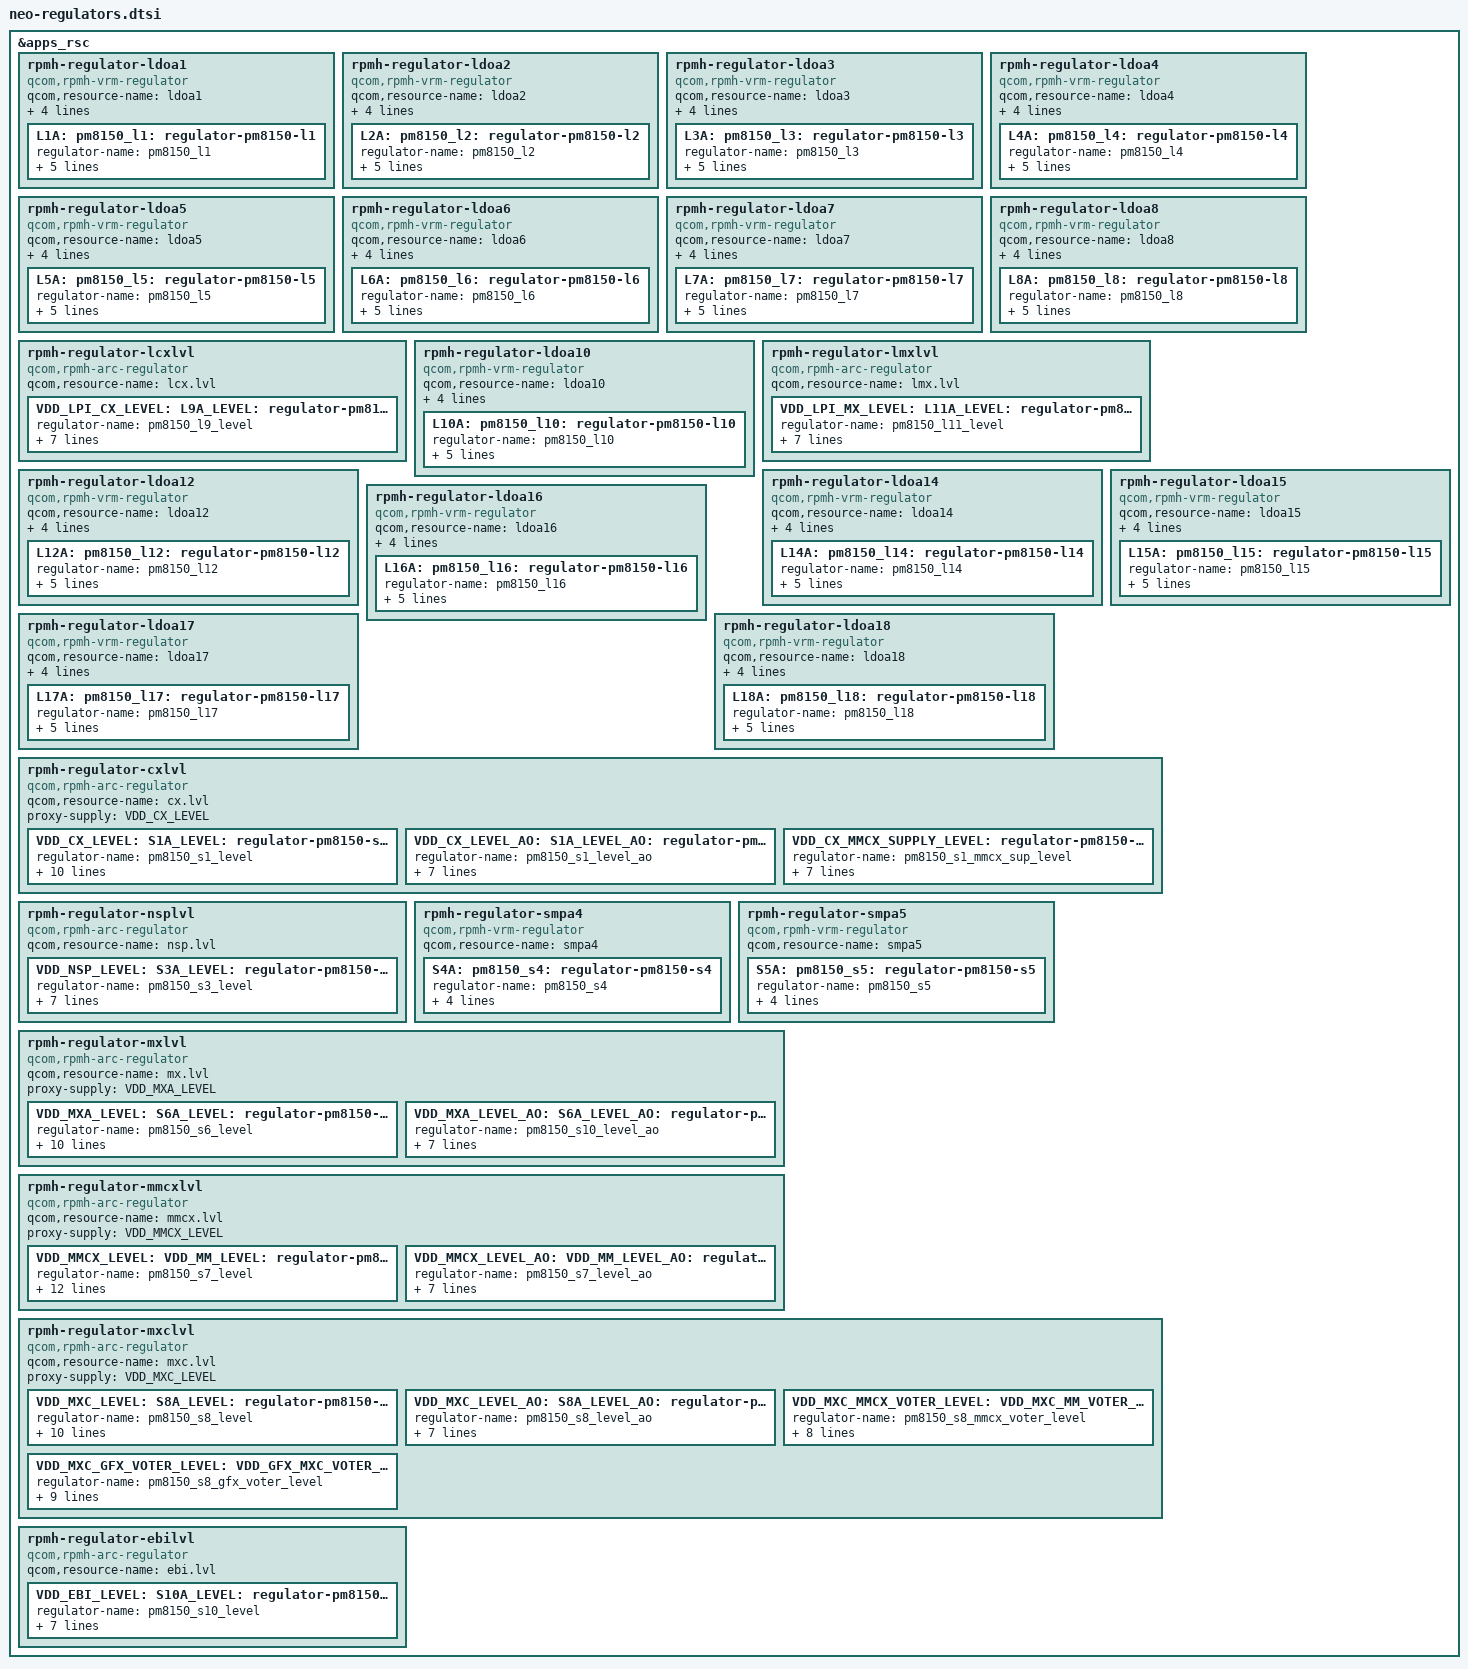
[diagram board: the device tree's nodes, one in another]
#include <dt-bindings/regulator/qcom,rpmh-regulator-levels.h>

&apps_rsc {
	rpmh-regulator-ldoa1 {
		compatible = "qcom,rpmh-vrm-regulator";
		qcom,resource-name = "ldoa1";
		qcom,regulator-type = "pmic5-ldo";
		qcom,supported-modes =
			<RPMH_REGULATOR_MODE_LPM
			 RPMH_REGULATOR_MODE_HPM>;
		qcom,mode-threshold-currents = <0 30000>;
		L1A:
		pm8150_l1: regulator-pm8150-l1 {
			regulator-name = "pm8150_l1";
			qcom,set = <RPMH_REGULATOR_SET_ALL>;
			regulator-min-microvolt = <830000>;
			regulator-max-microvolt = <920000>;
			qcom,init-voltage = <912000>;
			qcom,init-mode = <RPMH_REGULATOR_MODE_HPM>;
		};
	};

	rpmh-regulator-ldoa2 {
		compatible = "qcom,rpmh-vrm-regulator";
		qcom,resource-name = "ldoa2";
		qcom,regulator-type = "pmic5-ldo";
		qcom,supported-modes =
			<RPMH_REGULATOR_MODE_LPM
			RPMH_REGULATOR_MODE_HPM>;
		qcom,mode-threshold-currents = <0 10000>;
		L2A:
		pm8150_l2: regulator-pm8150-l2 {
			regulator-name = "pm8150_l2";
			qcom,set = <RPMH_REGULATOR_SET_ALL>;
			regulator-min-microvolt = <2700000>;
			regulator-max-microvolt = <3544000>;
			qcom,init-voltage = <3080000>;
			qcom,init-mode = <RPMH_REGULATOR_MODE_HPM>;
		};
	};

	rpmh-regulator-ldoa3 {
		compatible = "qcom,rpmh-vrm-regulator";
		qcom,resource-name = "ldoa3";
		qcom,regulator-type = "pmic5-ldo";
		qcom,supported-modes =
			<RPMH_REGULATOR_MODE_LPM
			RPMH_REGULATOR_MODE_HPM>;
		qcom,mode-threshold-currents = <0 30000>;
		L3A:
		pm8150_l3: regulator-pm8150-l3 {
			regulator-name = "pm8150_l3";
			qcom,set = <RPMH_REGULATOR_SET_ALL>;
			regulator-min-microvolt = <1080000>;
			regulator-max-microvolt = <1304000>;
			qcom,init-voltage = <1200000>;
			qcom,init-mode = <RPMH_REGULATOR_MODE_HPM>;
		};
	};

	rpmh-regulator-ldoa4 {
		compatible = "qcom,rpmh-vrm-regulator";
		qcom,resource-name = "ldoa4";
		qcom,regulator-type = "pmic5-ldo";
		qcom,supported-modes =
			<RPMH_REGULATOR_MODE_LPM
			RPMH_REGULATOR_MODE_HPM>;
		qcom,mode-threshold-currents = <0 30000>;
		L4A:
		pm8150_l4: regulator-pm8150-l4 {
			regulator-name = "pm8150_l4";
			qcom,set = <RPMH_REGULATOR_SET_ALL>;
			regulator-min-microvolt = <1150000>;
			regulator-max-microvolt = <1250000>;
			qcom,init-voltage = <1256000>;
			qcom,init-mode = <RPMH_REGULATOR_MODE_HPM>;
		};
	};

	rpmh-regulator-ldoa5 {
		compatible = "qcom,rpmh-vrm-regulator";
		qcom,resource-name = "ldoa5";
		qcom,regulator-type = "pmic5-ldo";
		qcom,supported-modes =
			<RPMH_REGULATOR_MODE_LPM
			RPMH_REGULATOR_MODE_HPM>;
		qcom,mode-threshold-currents = <0 30000>;
		L5A:
		pm8150_l5: regulator-pm8150-l5 {
			regulator-name = "pm8150_l5";
			qcom,set = <RPMH_REGULATOR_SET_ALL>;
			regulator-min-microvolt = <1010000>;
			regulator-max-microvolt = <1170000>;
			qcom,init-voltage = <1128000>;
			qcom,init-mode = <RPMH_REGULATOR_MODE_HPM>;
		};
	};

	rpmh-regulator-ldoa6 {
		compatible = "qcom,rpmh-vrm-regulator";
		qcom,resource-name = "ldoa6";
		qcom,regulator-type = "pmic5-ldo";
		qcom,supported-modes =
			<RPMH_REGULATOR_MODE_LPM
			RPMH_REGULATOR_MODE_HPM>;
		qcom,mode-threshold-currents = <0 30000>;
		L6A:
		pm8150_l6: regulator-pm8150-l6 {
			regulator-name = "pm8150_l6";
			qcom,set = <RPMH_REGULATOR_SET_ALL>;
			regulator-min-microvolt = <570000>;
			regulator-max-microvolt = <650000>;
			qcom,init-voltage = <600000>;
			qcom,init-mode = <RPMH_REGULATOR_MODE_HPM>;
		};
	};

	rpmh-regulator-ldoa7 {
		compatible = "qcom,rpmh-vrm-regulator";
		qcom,resource-name = "ldoa7";
		qcom,regulator-type = "pmic5-ldo";
		qcom,supported-modes =
			<RPMH_REGULATOR_MODE_LPM
			RPMH_REGULATOR_MODE_HPM>;
		qcom,mode-threshold-currents = <0 10000>;
		L7A:
		pm8150_l7: regulator-pm8150-l7 {
			regulator-name = "pm8150_l7";
			qcom,set = <RPMH_REGULATOR_SET_ALL>;
			regulator-min-microvolt = <1700000>;
			regulator-max-microvolt = <1950000>;
			qcom,init-voltage = <1800000>;
			qcom,init-mode = <RPMH_REGULATOR_MODE_HPM>;
		};
	};

	rpmh-regulator-ldoa8 {
		compatible = "qcom,rpmh-vrm-regulator";
		qcom,resource-name = "ldoa8";
		qcom,regulator-type = "pmic5-ldo";
		qcom,supported-modes =
			<RPMH_REGULATOR_MODE_LPM
			RPMH_REGULATOR_MODE_HPM>;
		qcom,mode-threshold-currents = <0 30000>;
		L8A:
		pm8150_l8: regulator-pm8150-l8 {
			regulator-name = "pm8150_l8";
			qcom,set = <RPMH_REGULATOR_SET_ALL>;
			regulator-min-microvolt = <720000>;
			regulator-max-microvolt = <950000>;
			qcom,init-voltage = <880000>;
			qcom,init-mode = <RPMH_REGULATOR_MODE_HPM>;
		};
	};

	rpmh-regulator-lcxlvl {
		compatible = "qcom,rpmh-arc-regulator";
		qcom,resource-name = "lcx.lvl";
		VDD_LPI_CX_LEVEL:
		L9A_LEVEL:
		pm8150_l9_level: regulator-pm8150-l9-level {
			regulator-name = "pm8150_l9_level";
			qcom,set = <RPMH_REGULATOR_SET_ALL>;
			regulator-min-microvolt =
				<RPMH_REGULATOR_LEVEL_RETENTION>;
			regulator-max-microvolt = <RPMH_REGULATOR_LEVEL_MAX>;
			qcom,init-voltage-level =
				<RPMH_REGULATOR_LEVEL_RETENTION>;
		};
	};

	rpmh-regulator-ldoa10 {
		compatible = "qcom,rpmh-vrm-regulator";
		qcom,resource-name = "ldoa10";
		qcom,regulator-type = "pmic5-ldo";
		qcom,supported-modes =
			<RPMH_REGULATOR_MODE_LPM
			RPMH_REGULATOR_MODE_HPM>;
		qcom,mode-threshold-currents = <0 10000>;
		L10A:
		pm8150_l10: regulator-pm8150-l10 {
			regulator-name = "pm8150_l10";
			qcom,set = <RPMH_REGULATOR_SET_ALL>;
			regulator-min-microvolt = <2700000>;
			regulator-max-microvolt = <3544000>;
			qcom,init-voltage = <2952000>;
			qcom,init-mode = <RPMH_REGULATOR_MODE_HPM>;
		};
	};

	rpmh-regulator-lmxlvl {
		compatible = "qcom,rpmh-arc-regulator";
		qcom,resource-name = "lmx.lvl";
		VDD_LPI_MX_LEVEL:
		L11A_LEVEL:
		pm8150_l11_level: regulator-pm8150-l11-level {
			regulator-name = "pm8150_l11_level";
			qcom,set = <RPMH_REGULATOR_SET_ALL>;
			regulator-min-microvolt =
				<RPMH_REGULATOR_LEVEL_RETENTION>;
			regulator-max-microvolt = <RPMH_REGULATOR_LEVEL_MAX>;
			qcom,init-voltage-level =
				<RPMH_REGULATOR_LEVEL_RETENTION>;
		};
	};

	rpmh-regulator-ldoa12 {
		compatible = "qcom,rpmh-vrm-regulator";
		qcom,resource-name = "ldoa12";
		qcom,regulator-type = "pmic5-ldo";
		qcom,supported-modes =
			<RPMH_REGULATOR_MODE_LPM
			RPMH_REGULATOR_MODE_HPM>;
		qcom,mode-threshold-currents = <0 10000>;
		L12A:
		pm8150_l12: regulator-pm8150-l12 {
			regulator-name = "pm8150_l12";
			qcom,set = <RPMH_REGULATOR_SET_ALL>;
			regulator-min-microvolt = <1504000>;
			regulator-max-microvolt = <2000000>;
			qcom,init-voltage = <1504000>;
			qcom,init-mode = <RPMH_REGULATOR_MODE_HPM>;
		};
	};

	rpmh-regulator-ldoa14 {
		compatible = "qcom,rpmh-vrm-regulator";
		qcom,resource-name = "ldoa14";
		qcom,regulator-type = "pmic5-ldo";
		qcom,supported-modes =
			<RPMH_REGULATOR_MODE_LPM
			RPMH_REGULATOR_MODE_HPM>;
		qcom,mode-threshold-currents = <0 10000>;
		L14A:
		pm8150_l14: regulator-pm8150-l14 {
			regulator-name = "pm8150_l14";
			qcom,set = <RPMH_REGULATOR_SET_ALL>;
			regulator-min-microvolt = <1620000>;
			regulator-max-microvolt = <2000000>;
			qcom,init-voltage = <1620000>;
			qcom,init-mode = <RPMH_REGULATOR_MODE_HPM>;
		};
	};

	rpmh-regulator-ldoa15 {
		compatible = "qcom,rpmh-vrm-regulator";
		qcom,resource-name = "ldoa15";
		qcom,regulator-type = "pmic5-ldo";
		qcom,supported-modes =
			<RPMH_REGULATOR_MODE_LPM
			RPMH_REGULATOR_MODE_HPM>;
		qcom,mode-threshold-currents = <0 10000>;
		L15A:
		pm8150_l15: regulator-pm8150-l15 {
			regulator-name = "pm8150_l15";
			qcom,set = <RPMH_REGULATOR_SET_ALL>;
			regulator-min-microvolt = <1540000>;
			regulator-max-microvolt = <2000000>;
			qcom,init-voltage = <1800000>;
			qcom,init-mode = <RPMH_REGULATOR_MODE_HPM>;
		};
	};

	rpmh-regulator-ldoa16 {
		compatible = "qcom,rpmh-vrm-regulator";
		qcom,resource-name = "ldoa16";
		qcom,regulator-type = "pmic5-ldo";
		qcom,supported-modes =
			<RPMH_REGULATOR_MODE_LPM
			RPMH_REGULATOR_MODE_HPM>;
		qcom,mode-threshold-currents = <0 10000>;
		L16A:
		pm8150_l16: regulator-pm8150-l16 {
			regulator-name = "pm8150_l16";
			qcom,set = <RPMH_REGULATOR_SET_ALL>;
			regulator-min-microvolt = <1504000>;
			regulator-max-microvolt = <3544000>;
			qcom,init-voltage = <2600000>;
			qcom,init-mode = <RPMH_REGULATOR_MODE_HPM>;
		};
	};

	rpmh-regulator-ldoa17 {
		compatible = "qcom,rpmh-vrm-regulator";
		qcom,resource-name = "ldoa17";
		qcom,regulator-type = "pmic5-ldo";
		qcom,supported-modes =
			<RPMH_REGULATOR_MODE_LPM
			RPMH_REGULATOR_MODE_HPM>;
		qcom,mode-threshold-currents = <0 10000>;
		L17A:
		pm8150_l17: regulator-pm8150-l17 {
			regulator-name = "pm8150_l17";
			qcom,set = <RPMH_REGULATOR_SET_ALL>;
			regulator-min-microvolt = <3200000>;
			regulator-max-microvolt = <3544000>;
			qcom,init-voltage = <3200000>;
			qcom,init-mode = <RPMH_REGULATOR_MODE_HPM>;
		};
	};

	rpmh-regulator-ldoa18 {
		compatible = "qcom,rpmh-vrm-regulator";
		qcom,resource-name = "ldoa18";
		qcom,regulator-type = "pmic5-ldo";
		qcom,supported-modes =
			<RPMH_REGULATOR_MODE_LPM
			RPMH_REGULATOR_MODE_HPM>;
		qcom,mode-threshold-currents = <0 30000>;
		L18A:
		pm8150_l18: regulator-pm8150-l18 {
			regulator-name = "pm8150_l18";
			qcom,set = <RPMH_REGULATOR_SET_ALL>;
			regulator-min-microvolt = <552000>;
			regulator-max-microvolt = <1304000>;
			qcom,init-voltage = <1200000>;
			qcom,init-mode = <RPMH_REGULATOR_MODE_HPM>;
		};
	};

	rpmh-regulator-cxlvl {
		compatible = "qcom,rpmh-arc-regulator";
		qcom,resource-name = "cx.lvl";
		proxy-supply = <&VDD_CX_LEVEL>;

		VDD_CX_LEVEL: S1A_LEVEL:
		pm8150_s1_level: regulator-pm8150-s1-level {
			regulator-name = "pm8150_s1_level";
			qcom,set = <RPMH_REGULATOR_SET_ALL>;
			regulator-min-microvolt =
				<RPMH_REGULATOR_LEVEL_RETENTION>;
			regulator-max-microvolt =
				<RPMH_REGULATOR_LEVEL_MAX>;
			qcom,init-voltage-level =
				<RPMH_REGULATOR_LEVEL_TURBO>;
			qcom,proxy-consumer-enable;
			qcom,proxy-consumer-voltage =
				<RPMH_REGULATOR_LEVEL_TURBO
				 RPMH_REGULATOR_LEVEL_MAX>;
		};

		VDD_CX_LEVEL_AO: S1A_LEVEL_AO:
		pm8150_s1_level_ao: regulator-pm8150-s1-level-ao {
			regulator-name = "pm8150_s1_level_ao";
			qcom,set = <RPMH_REGULATOR_SET_ACTIVE>;
			regulator-min-microvolt =
				<RPMH_REGULATOR_LEVEL_RETENTION>;
			regulator-max-microvolt =
				<RPMH_REGULATOR_LEVEL_MAX>;
			qcom,init-voltage-level =
				<RPMH_REGULATOR_LEVEL_RETENTION>;
		};

		VDD_CX_MMCX_SUPPLY_LEVEL: regulator-pm8150-s1-mmcx-sup-level {
			regulator-name = "pm8150_s1_mmcx_sup_level";
			qcom,set = <RPMH_REGULATOR_SET_ALL>;
			regulator-min-microvolt =
				<RPMH_REGULATOR_LEVEL_MIN_SVS>;
			regulator-max-microvolt =
				<RPMH_REGULATOR_LEVEL_MAX>;
			qcom,init-voltage-level =
				<RPMH_REGULATOR_LEVEL_MIN_SVS>;
		};
	};

	rpmh-regulator-nsplvl {
		compatible = "qcom,rpmh-arc-regulator";
		qcom,resource-name = "nsp.lvl";
		VDD_NSP_LEVEL: S3A_LEVEL:
		pm8150_s3_level: regulator-pm8150-s3-level {
			regulator-name = "pm8150_s3_level";
			qcom,set = <RPMH_REGULATOR_SET_ALL>;
			regulator-min-microvolt =
				<RPMH_REGULATOR_LEVEL_RETENTION>;
			regulator-max-microvolt =
				<RPMH_REGULATOR_LEVEL_MAX>;
			qcom,init-voltage-level =
				<RPMH_REGULATOR_LEVEL_RETENTION>;
		};
	};

	rpmh-regulator-smpa4 {
		compatible = "qcom,rpmh-vrm-regulator";
		qcom,resource-name = "smpa4";
		S4A: pm8150_s4: regulator-pm8150-s4 {
			regulator-name = "pm8150_s4";
			qcom,set = <RPMH_REGULATOR_SET_ALL>;
			regulator-min-microvolt = <470000>;
			regulator-max-microvolt = <1170000>;
			qcom,init-voltage = <950000>;
		};
	};

	rpmh-regulator-smpa5 {
		compatible = "qcom,rpmh-vrm-regulator";
		qcom,resource-name = "smpa5";
		S5A: pm8150_s5: regulator-pm8150-s5 {
			regulator-name = "pm8150_s5";
			qcom,set = <RPMH_REGULATOR_SET_ALL>;
			regulator-min-microvolt = <1504000>;
			regulator-max-microvolt = <2040000>;
			qcom,init-voltage = <1856000>;
		};
	};

	rpmh-regulator-mxlvl {
		compatible = "qcom,rpmh-arc-regulator";
		qcom,resource-name = "mx.lvl";
		proxy-supply = <&VDD_MXA_LEVEL>;

		VDD_MXA_LEVEL: S6A_LEVEL:
		pm8150_s6_level: regulator-pm8150-s6-level {
			regulator-name = "pm8150_s6_level";
			qcom,set = <RPMH_REGULATOR_SET_ALL>;
			regulator-min-microvolt =
				<RPMH_REGULATOR_LEVEL_RETENTION>;
			regulator-max-microvolt =
				<RPMH_REGULATOR_LEVEL_MAX>;
			qcom,init-voltage-level =
				<RPMH_REGULATOR_LEVEL_TURBO>;
			qcom,proxy-consumer-enable;
			qcom,proxy-consumer-voltage =
				<RPMH_REGULATOR_LEVEL_TURBO
				 RPMH_REGULATOR_LEVEL_MAX>;
		};

		VDD_MXA_LEVEL_AO: S6A_LEVEL_AO:
		pm8150_s6_level_ao: regulator-pm8150-s6-level-ao {
			regulator-name = "pm8150_s10_level_ao";
			qcom,set = <RPMH_REGULATOR_SET_ACTIVE>;
			regulator-min-microvolt =
				<RPMH_REGULATOR_LEVEL_RETENTION>;
			regulator-max-microvolt =
				<RPMH_REGULATOR_LEVEL_MAX>;
			qcom,init-voltage-level =
				<RPMH_REGULATOR_LEVEL_RETENTION>;
		};
	};

	rpmh-regulator-mmcxlvl {
		compatible = "qcom,rpmh-arc-regulator";
		qcom,resource-name = "mmcx.lvl";
		proxy-supply = <&VDD_MMCX_LEVEL>;
		VDD_MMCX_LEVEL:
		VDD_MM_LEVEL:
		S7A_LEVEL:
		pm8150_s7_level: regulator-pm8150-s7-level {
			regulator-name = "pm8150_s7_level";
			qcom,set = <RPMH_REGULATOR_SET_ALL>;
			pm8150_s7_level-parent-supply =
				<&VDD_CX_MMCX_SUPPLY_LEVEL>;
			regulator-min-microvolt =
				<RPMH_REGULATOR_LEVEL_RETENTION>;
			regulator-max-microvolt = <RPMH_REGULATOR_LEVEL_MAX>;
			qcom,init-voltage-level =
				<RPMH_REGULATOR_LEVEL_TURBO>;
			qcom,proxy-consumer-enable;
			qcom,proxy-consumer-voltage =
				<RPMH_REGULATOR_LEVEL_TURBO
				 RPMH_REGULATOR_LEVEL_MAX>;
		};

		VDD_MMCX_LEVEL_AO:
		VDD_MM_LEVEL_AO:
		S7A_LEVEL_AO:
		pm8150_s7_level_ao: regulator-pm8150-s7-level-ao {
			regulator-name = "pm8150_s7_level_ao";
			qcom,set = <RPMH_REGULATOR_SET_ACTIVE>;
			regulator-min-microvolt =
				<RPMH_REGULATOR_LEVEL_RETENTION>;
			regulator-max-microvolt = <RPMH_REGULATOR_LEVEL_MAX>;
			qcom,init-voltage-level =
				<RPMH_REGULATOR_LEVEL_RETENTION>;
		};
	};

	rpmh-regulator-mxclvl {
		compatible = "qcom,rpmh-arc-regulator";
		qcom,resource-name = "mxc.lvl";
		proxy-supply = <&VDD_MXC_LEVEL>;

		VDD_MXC_LEVEL: S8A_LEVEL:
		pm8150_s8_level: regulator-pm8150-s8-level {
			regulator-name = "pm8150_s8_level";
			qcom,set = <RPMH_REGULATOR_SET_ALL>;
			regulator-min-microvolt =
				<RPMH_REGULATOR_LEVEL_RETENTION>;
			regulator-max-microvolt =
				<RPMH_REGULATOR_LEVEL_MAX>;
			qcom,init-voltage-level =
				<RPMH_REGULATOR_LEVEL_TURBO>;
			qcom,proxy-consumer-enable;
			qcom,proxy-consumer-voltage =
				<RPMH_REGULATOR_LEVEL_TURBO
				 RPMH_REGULATOR_LEVEL_MAX>;
		};

		VDD_MXC_LEVEL_AO: S8A_LEVEL_AO:
		pm8150_s8_level_ao: regulator-pm8150-s8-level-ao {
			regulator-name = "pm8150_s8_level_ao";
			qcom,set = <RPMH_REGULATOR_SET_ACTIVE>;
			regulator-min-microvolt =
				<RPMH_REGULATOR_LEVEL_RETENTION>;
			regulator-max-microvolt =
				<RPMH_REGULATOR_LEVEL_MAX>;
			qcom,init-voltage-level =
				<RPMH_REGULATOR_LEVEL_RETENTION>;
		};

		VDD_MXC_MMCX_VOTER_LEVEL: VDD_MXC_MM_VOTER_LEVEL:
		VDD_MM_MXC_VOTER_LEVEL:
		regulator-pm8150-s8-mmcx-voter-level {
			regulator-name = "pm8150_s8_mmcx_voter_level";
			vin-supply = <&VDD_MMCX_LEVEL>;
			qcom,set = <RPMH_REGULATOR_SET_ALL>;
			regulator-min-microvolt =
				<RPMH_REGULATOR_LEVEL_MIN_SVS>;
			regulator-max-microvolt =
				<RPMH_REGULATOR_LEVEL_MAX>;
			qcom,init-voltage-level =
				<RPMH_REGULATOR_LEVEL_MIN_SVS>;
		};

		VDD_MXC_GFX_VOTER_LEVEL: VDD_GFX_MXC_VOTER_LEVEL:
		regulator-pm8150-s8-gfx-voter-level {
			regulator-name = "pm8150_s8_gfx_voter_level";
			pm8150_s8_gfx_voter_level-parent-supply =
				<&VDD_GFX_LEVEL>;
			qcom,set = <RPMH_REGULATOR_SET_ALL>;
			regulator-min-microvolt =
				<RPMH_REGULATOR_LEVEL_MIN_SVS>;
			regulator-max-microvolt =
				<RPMH_REGULATOR_LEVEL_MAX>;
			qcom,init-voltage-level =
				<RPMH_REGULATOR_LEVEL_MIN_SVS>;
		};
	};

	rpmh-regulator-ebilvl {
		compatible = "qcom,rpmh-arc-regulator";
		qcom,resource-name = "ebi.lvl";
		VDD_EBI_LEVEL: S10A_LEVEL:
		pm8150_s10_level: regulator-pm8150-s10-level {
			regulator-name = "pm8150_s10_level";
			qcom,set = <RPMH_REGULATOR_SET_ALL>;
			regulator-min-microvolt =
				<RPMH_REGULATOR_LEVEL_RETENTION>;
			regulator-max-microvolt =
				<RPMH_REGULATOR_LEVEL_MAX>;
			qcom,init-voltage-level =
				<RPMH_REGULATOR_LEVEL_RETENTION>;
		};
	};
};
